# UNIPRO_REG register map
Vendor: Texas Instruments
Registers are 32-bit, access per field, reset 0x0 unless marked. A register's access mark holds for its fields unless they carry their own. Offsets are as the file gives them; [hi:lo] are bit positions; {n}, {i} and the like mark numbered series; 'fields as' and 'values as' point back to an identical list.

## UNIPRO_REG (part 2 of 2)
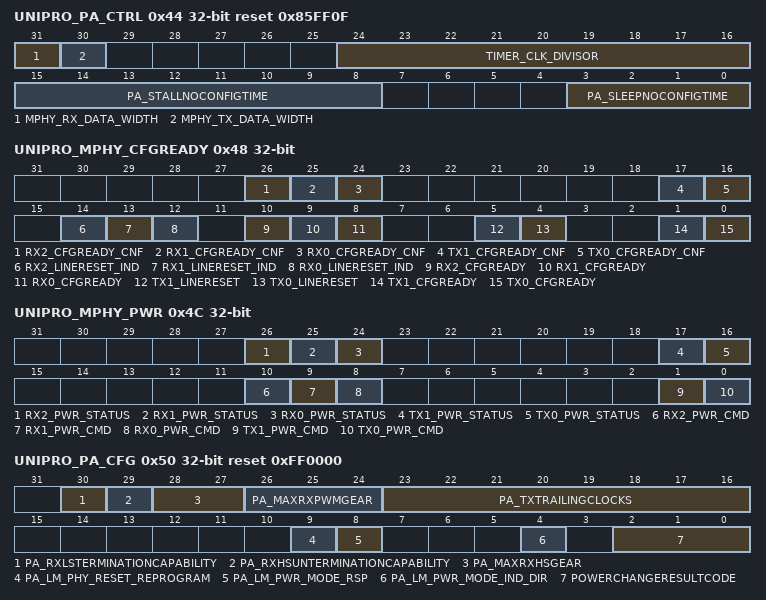
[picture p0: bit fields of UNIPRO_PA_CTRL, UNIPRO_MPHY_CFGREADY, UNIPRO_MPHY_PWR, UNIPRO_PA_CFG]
0x44 UNIPRO_PA_CTRL reset 0x85FF0F — This register programs UniPro PA general configuration and control.
  [31] MPHY_RX_DATA_WIDTH rw — Defines the width of the Data Bus on Rx. 0: 8 bits 1: 16 bits
  [30] MPHY_TX_DATA_WIDTH rw — Defines the width of the Data Bus on Tx. 0: 8 bits 1: 16 bits
  [24:16] TIMER_CLK_DIVISOR rw — Defines the ratio to be used for the generation of the timer clocks. Valid values 0x001-0x1FF. If CLKSEL_OPP = '0' the programmed value is used. If CLKSEL_OPP = '1' the value is multiplied by 2.
  [15:8] PA_STALLNOCONFIGTIME rw — Specifies the minimum time to wait between bursts in HS mode expressed in Symbol Intervals.
  [3:0] PA_SLEEPNOCONFIGTIME rw — Specifies the minimum time to wait between bursts in PWM mode expressed in Symbol Intervals.
0x48 UNIPRO_MPHY_CFGREADY — This register control MPHY_CFGREADY requests to M-TX/M-RX and monitors confirms.
  [26] RX2_CFGREADY_CNF ro — CFGREADY.cnf received for M-RX2. Cleared by HW when new command is issued.
  [25] RX1_CFGREADY_CNF ro — CFGREADY.cnf received for M-RX1. Cleared by HW when new command is issued.
  [24] RX0_CFGREADY_CNF ro — CFGREADY.cnf received for M-RX0. Cleared by HW when new command is issued.
  [17] TX1_CFGREADY_CNF ro — CFGREADY.cnf or LINERESET.cnf received for M-TX1. Cleared by HW when new command is issued.
  [16] TX0_CFGREADY_CNF ro — CFGREADY.cnf or LINERESET.cnf received for M-TX0. Cleared by HW when new command is issued.
  [14] RX2_LINERESET_IND rw — Indicate LINERESET occurred for M-RX2. Cleared by SW.
  [13] RX1_LINERESET_IND rw — Indicate LINERESET occurred for M-RX1. Cleared by SW.
  [12] RX0_LINERESET_IND rw — Indicate LINERESET occurred for M-RX0. Cleared by SW.
  [10] RX2_CFGREADY wo — Sets CFGREADY for M-RX2.
  [9] RX1_CFGREADY wo — Sets CFGREADY for M-RX1.
  [8] RX0_CFGREADY wo — Sets CFGREADY for M-RX0
  [5] TX1_LINERESET wo — Sets LINERESET for M-TX1.
  [4] TX0_LINERESET wo — Sets LINERESET for M-TX0
  [1] TX1_CFGREADY wo — Sets CFGREADY for M-TX1.
  [0] TX0_CFGREADY wo — Sets CFGREADY for M-TX0
0x4C UNIPRO_MPHY_PWR — Tx/Rx M-PHY power control
  [26] RX2_PWR_STATUS ro — Status of the M-RX2. Read 0x0: M-RX in OFF state Read 0x1: M-RX in ON state
  [25] RX1_PWR_STATUS ro — Status of the M-RX1. Read 0x0: M-RX in OFF state Read 0x1: M-RX in ON state
  [24] RX0_PWR_STATUS ro — Status of the M-RX0 Read 0x0: M-RX in OFF state Read 0x1: M-RX in ON state
  [17] TX1_PWR_STATUS ro — Status of the power control of M-TX1. Read 0x0: M-TX in OFF state Read 0x1: M-TX in ON state
  [16] TX0_PWR_STATUS ro — Status of the power control of M-TX0 Read 0x0: M-TX in OFF state Read 0x1: M-TX in ON state
  [10] RX2_PWR_CMD rw — Command for power control of M-RX2. 0x0: Command to change to OFF state 0x1: Command to change to ON state
  [9] RX1_PWR_CMD rw — Command for power control of M-RX1. 0x0: Command to change to OFF state 0x1: Command to change to ON state
  [8] RX0_PWR_CMD rw — Command for power control of M-RX0 0x0: Command to change to OFF state 0x1: Command to change to ON state
  [1] TX1_PWR_CMD rw — Command for power control of M-TX1. 0x0: Command to change to OFF state 0x1: Command to change to ON state
  [0] TX0_PWR_CMD rw — Command for power control of M-TX0 0x0: Command to change to OFF state 0x1: Command to change to ON state
0x50 UNIPRO_PA_CFG access not given reset 0xFF0000 — PHYSICAL ADAPTER CONFIGURATION REGISTER This register contains, amongst other, the PA_MIB.
  [30] PA_RXLSTERMINATIONCAPABILITY rw — Specifies whether or not the inbound link supports terminated line in LS mode.
  [29] PA_RXHSUNTERMINATIONCAPABILITY rw — Specifies whether or not the inbound link supports unterminated line in HS mode.
  [28:27] PA_MAXRXHSGEAR rw — Maximum RX High Speed Gears (HS), 0 means no HS available 0: NO_HS 1: HS_G1 2: HS_G2 3: HS_G3
  [26:24] PA_MAXRXPWMGEAR rw — Maximum RX Low Speed Gear (PWM) 0: Reserved 1: PWM_G1 2: PWM_G2 3: PWM_G3 4: PWM_G4 5: PWM_G5 6: PWM_G6 7: PWM_G7
  [23:16] PA_TXTRAILINGCLOCKS rw — Number of PHY byte clock cycles forced without data before a mode change from FAST_STATE or SLOW_STATE to SLEEP_STATE, or before data transmission pause while in FAST_STATE or SLOW_STATE.
  [9] PA_LM_PHY_RESET_REPROGRAM wo — Indicates SW has reprogrammed PHY attributes after a PHY_RESET. 0:SW has not reprogrammed PHY attributes. 1:SW has reprogrammed PHY attributes.
  [8] PA_LM_PWR_MODE_RSP wo — Response to PA_LM_PWR_MODE.ind Writing a 1 to this field confirms that PA_LM_PWR_MODE.ind is accepted and PA_PWRModeUserData fields are updated.
  [4] PA_LM_PWR_MODE_IND_DIR — Indicates whether PA_LM_PWR_MODE.ind was from local or remote request. 0: remote request 1: local request (access RW WtoClr)
  [2:0] POWERCHANGERESULTCODE — The code of the accepted Power Change requets 0: PWR_OK - The request was accepted. 1: PWR_LOCAL - The local request was successfully applied 2: PWR_REMOTE - The remote request was successfully applied 3: PWR_BUSY - The request was aborted due to concurrent requests 4: PWR_ERROR_CAP - The request was rejected due to an impossible configuration. 5: PWR_FATAL_ERROR - The request was aborted due to a communication problem. The link may be inoperable. 6-7: reserved Write to clear. (access RW WtoClr)
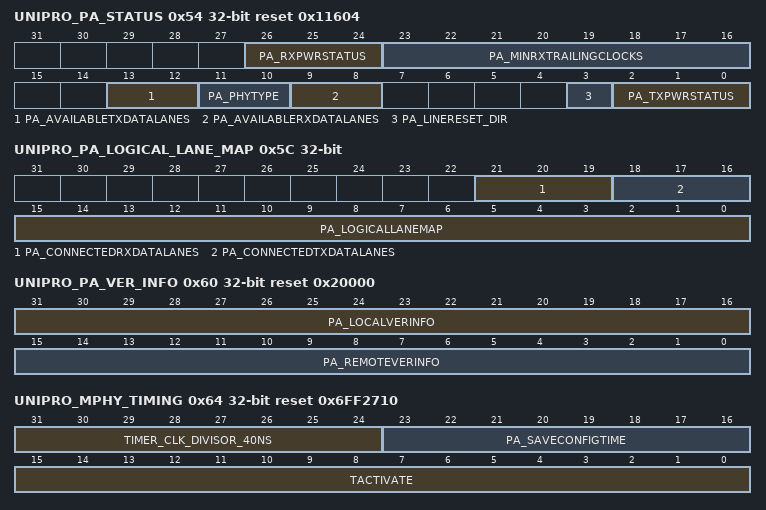
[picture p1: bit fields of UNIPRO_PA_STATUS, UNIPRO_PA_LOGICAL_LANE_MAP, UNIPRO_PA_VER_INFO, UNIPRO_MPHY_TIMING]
0x54 UNIPRO_PA_STATUS ro reset 0x11604 — PHYSICAL ADAPTER STATUS REGISTER This register contains, amongst other, the PA_MIB.
  [26:24] PA_RXPWRSTATUS — Power status for Rx 0x0 Off_state 0x1 Fast_state 0x2 Slow_state 0x3 Hibernate_state (ULPS State) 0x4 Sleep_state (STOP state) Reading this field actually triggers an M-CTRL-CFGGET request to the M-RX. The RX_FSM attribute is read for logical lane 0 and this is the value returned.
  [23:16] PA_MINRXTRAILINGCLOCKS — Minimum number of PHY byte clock without data to receive before a mode change from FAST_STATE or SLOW_STATE to SLEEP_STATE, or before a pause in data transmission when in FAST_STATE or SLOW_STATE
  [13:12] PA_AVAILABLETXDATALANES — 0x0 1 lane 0x1 2 lanes 0x2 3 lanes 0x3 4 lanes (Programmed_Value = MIPI_Specified_Value - 1)
  [11:10] PA_PHYTYPE — 0x0: encode D PHY 0x1: M PHY 0x2: reserved 0x3: reserved
  [9:8] PA_AVAILABLERXDATALANES — 0x0 1 lane 0x1 2 lanes 0x2 3 lanes 0x3 4 lanes (Programmed_Value = MIPI_Specified_Value - 1)
  [3] PA_LINERESET_DIR — Indicates whether LINERESET was for M-RX or M-TX 0x0 M-RX 0x1 M-TX
  [2:0] PA_TXPWRSTATUS — Power status for Tx 0x0 Off_state 0x1 Fast_state 0x2 Slow_state 0x3 Hibernate_state (ULPS State) 0x4 Sleep_state (STOP state) Reading this field actually triggers an M-CTRL-CFGGET request to the M-TX. The TX_FSM attribute is read for logical lane 0 and this is the value returned.
0x5C UNIPRO_PA_LOGICAL_LANE_MAP — PHYSICAL ADAPTER STATUS REGISTER This register contains, amongst other, the PA_MIB. Note: this register is only writable in PHY Test mode
  [21:19] PA_CONNECTEDRXDATALANES rw — Number of Rx Data Lanes Connected 0x0 0 lanes 0x1 1 lane 0x2 2 lanes 0x3 3 lanes 0x4 4 lanes
  [18:16] PA_CONNECTEDTXDATALANES rw — Number of Tx Data Lanes Connected 0x0 0 lanes 0x1 1 lane 0x2 2 lanes 0x3 3 lanes 0x4 4 lanes
  [15:0] PA_LOGICALLANEMAP rw — Logical to Physical Lane mapping. Fields contain a valid value after succesfull Linkstartup sequence. Tx Lanes: Bits 1..0: Physical lane of logical lane 0 Bits 3..2: Physical lane of logical lane 1 Bits 5..4: Physical lane of logical lane 2 Bits 7..6: Physical lane of logical lane 3 Rx Lanes: Bits 9..8: Physical lane of logical lane 0 Bits 11..10: Physical lane of logical lane 1 Bits 13..12: Physical lane of logical lane 2 Bits 15..14: Physical lane of logical lane 3
0x60 UNIPRO_PA_VER_INFO reset 0x20000 — This register contains version information.
  [31:16] PA_LOCALVERINFO rw — Local Version Info. Delivered during the Link Startup Sequence to the peer and stored to there.
  [15:0] PA_REMOTEVERINFO ro — Remote Peer's version information. Available after Link Startup Sequence.
0x64 UNIPRO_MPHY_TIMING rw reset 0x6FF2710 — This register defines the timing parameters that need to be respected on the M-PHY Control Interface..
  [31:24] TIMER_CLK_DIVISOR_40NS — Defines the ratio to be used for the generation of a 40ns clock from UniPro OCP functional clock. Legal values 0x01 - 0xFF. If CLKSEL_OPP = '0' the programmed value is used. If CLKSEL_OPP = '1' the value is multiplied by 2.
  [23:16] PA_SAVECONFIGTIME — Minimum reconfiguration time (expressed in 40 ns intervals). Downgraded value updated after Linkstartup completes.
  [15:0] TACTIVATE — The period of time that M-TX shall drive DIF-N on the lines. The time is expressed in us. This field should be programmed to satisfy MPHY’s requirements for TACTIVATE and T_LINE_RESET. The time should be greater than MAX(TACTIVATE, T_LINE_RESET).
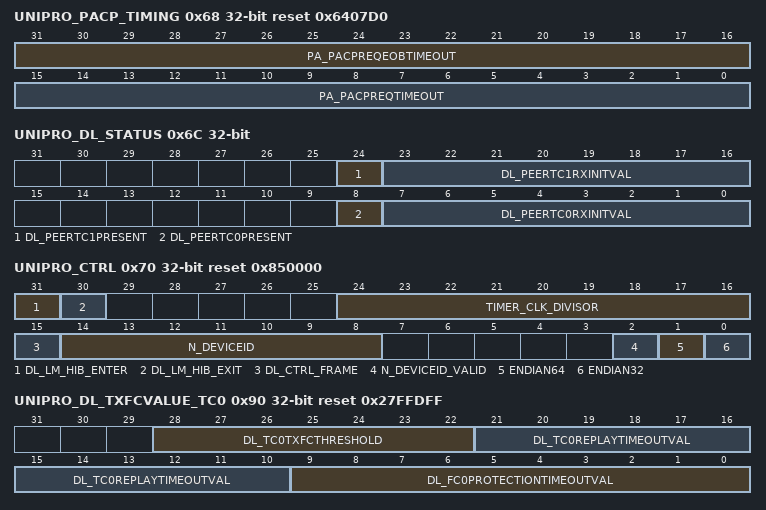
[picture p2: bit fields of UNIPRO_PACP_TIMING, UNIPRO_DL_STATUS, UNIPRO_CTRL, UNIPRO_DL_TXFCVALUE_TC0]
0x68 UNIPRO_PACP_TIMING rw reset 0x6407D0 — This register contains the timeout values for .
  [31:16] PA_PACPREQEOBTIMEOUT — Expiration value of the PACP_REQUEST_EoB_TIMER. The value is expressed in us.
  [15:0] PA_PACPREQTIMEOUT — Expiration value of the PACP_REQUEST_TIMER. The value is expressed in us.
0x6C UNIPRO_DL_STATUS ro — DATA LINK STATUS REGISTER This register contains DL status information.
  [24] DL_PEERTC1PRESENT — This status bit is updated during the initilization phase following the DL_ENABLE_LAYER.req() command. It is set to zero by default. 0: indicates that the Peer Device does not support TC0 1: indicates that the Peer Device does support TC0
  [23:16] DL_PEERTC1RXINITVAL — This register get set after DL initilization. It is loaded with the credit value sent by the remote device on the first AFC exchange during the boot sequence.
  [8] DL_PEERTC0PRESENT — This status bit is updated during the initilization phase following the DL_ENABLE_LAYER.req() command. It is set to zero by default. 0: indicates that the Peer Device does not support TC0 1: indicates that the Peer Device does support TC0
  [7:0] DL_PEERTC0RXINITVAL — This register get set after DL initilization. It is loaded with the credit value sent by the remote device on the first AFC exchange during the boot sequence.
0x70 UNIPRO_CTRL reset 0x850000 — This register regroups UniPro interface general control and configuration parameters
  [31] DL_LM_HIB_ENTER wo — Write 1 to this field to trigger DL_LM_HIBERNATE_ENTER.req
  [30] DL_LM_HIB_EXIT wo — Write 1 to this field to trigger DL_LM_HIBERNATE_EXIT.req
  [24:16] TIMER_CLK_DIVISOR rw — Defines the ratio to be used for the generation of the Timer clock from UniPro OCP functional clock. Legal values 0x001 - 0x1FF. If CLKSEL_OPP = '0' the programmed value is used. If CLKSEL_OPP = '1' the value is multiplied by 2.
  [15] DL_CTRL_FRAME ro — When 1, Indicates that Data Link engine has scheduled control frames whose transmission is not completed. When 0, all scheduled control frames in Data Link have been transmitted.
  [14:8] N_DEVICEID rw — local DeviceID value
  [2] N_DEVICEID_VALID rw — N_DeviceID attribute is valid. 0: N_DeviceID attribute is not valid. DeviceIDOffset = 0. 1: N_DeviceID attribute is valid. DeviceIDOffset = DestDeviceID_Enc - N_DeviceID
  [1] ENDIAN64 rw — 64b word Data Receive endianness conversion control 0 : no endianness adaptation 1 : the two 32b halves constituting the 64b are swizzled
  [0] ENDIAN32 rw — 32b word Data Receive endianness conversion control 0 : no endianness adaptation 1 : bytes in a 32b word are swizzled
0x74 UNIPRO_MPHY_TIMING2 reset 0x2710 — This register defines timing parameters on the M-PHY Control Interface.
  [15:0] PA_HIBERN8TIME rw — The period of time in which M-TX must remain in Hibern8 once entered. Time is expressed in usec.
0x7C UNIPRO_PA_LM_ENABLE_LAYER wo — PHYSICAL ADAPTER Command writing to the register initiates a link start up. The DME command has been renamedas PA_LM_ENABLE.req
  [31:0] VALUE
0x80 UNIPRO_DL_LM_ENABLE_LAYER wo — Data Link Layer Command writing to the register initializes the data link layer. This corresponds to the DME command DL_LM_ENABLE_LAYER.req
  [31:0] VALUE
0x84 UNIPRO_N_LM_ENABLE_LAYER wo — Network Layer Command writing to the memory mapped address initiates a N_LM_ENABLE.req
  [31:0] VALUE
0x88 UNIPRO_T_LM_ENABLE_LAYER wo — Transport Layer Command writing to the memory mapped address initiates a T_LM_ENABLE.req ref. to UniPro 1.1 release [3].
  [31:0] VALUE
0x8C UNIPRO_ENDPOINTRESET wo — PHYSICAL ADAPTER Command writing to the register initiates transmission of an EndPointReset trgigger over the link to the peer device.
  [31:0] VALUE
0x90 UNIPRO_DL_TXFCVALUE_TC0 reset 0x27FFDFF — DATA LINK TX flow control value This register contains the timeout and threshold values for DL MIB for transmitter side
  [28:22] DL_TC0TXFCTHRESHOLD rw — Threshold for triggering an AFC0 frame with REQ bit set to request flow control update from the remote end
  [21:10] DL_TC0REPLAYTIMEOUTVAL rw — 1 to 4095 us. (1 MHz clock derived from 1.6GHz) Timeout value for triggering retransmission of TC0 frame. Zero indicates timer is OFF
  [9:0] DL_FC0PROTECTIONTIMEOUTVAL rw — 1 to 1023 us. (1 MHz clock derived from 1.6GHz) Timeout value for triggering a request to remote end for flow control update. Zero indicates timer is OFF
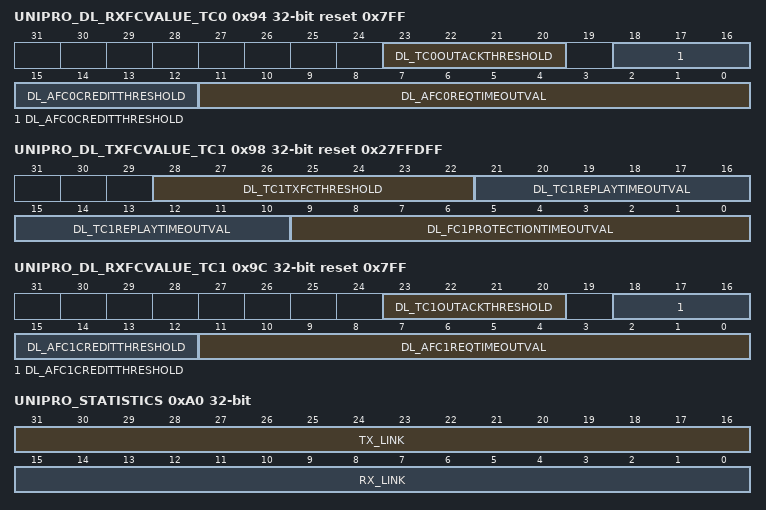
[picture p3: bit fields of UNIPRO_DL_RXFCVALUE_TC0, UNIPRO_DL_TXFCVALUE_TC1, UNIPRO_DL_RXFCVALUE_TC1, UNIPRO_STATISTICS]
0x94 UNIPRO_DL_RXFCVALUE_TC0 reset 0x7FF — DATA LINK RX flow control values This register contains the timeout and threshold values for DL MIB for receiver side
  [23:20] DL_TC0OUTACKTHRESHOLD rw — 0 to 15. Number of outstanding Acknowledgements for TC0
  [18:12] DL_AFC0CREDITTHRESHOLD rw — 0 to 127 Threshold for AFC triggering based on available credits
  [11:0] DL_AFC0REQTIMEOUTVAL rw — 1 to 4095 us. (1 MHz clock derived from 1.6GHz) TimeOut value for AFC triggering on receiver side. Zero indicates that the timer is OFF
0x98 UNIPRO_DL_TXFCVALUE_TC1 reset 0x27FFDFF — DATA LINK TX flow control value This register contains the timeout and threshold values for DL MIB for transmitter side
  [28:22] DL_TC1TXFCTHRESHOLD rw — Threshold for triggering an AFC1 frame with REQ bit set to request flow control update from the remote end
  [21:10] DL_TC1REPLAYTIMEOUTVAL rw — 1 to 4095 us. (1 MHz clock derived from 1.6GHz) Timeout value for triggering retransmission of TC1 frame. Zero indicates timer is OFF
  [9:0] DL_FC1PROTECTIONTIMEOUTVAL rw — 1 to 1023 us. (1 MHz clock derived from 1.6GHz) Timeout value for triggering a request to remote end for flow control update. Zero indicates timer is OFF
0x9C UNIPRO_DL_RXFCVALUE_TC1 reset 0x7FF — DATA LINK RX flow control values This register contains the timeout and threshold values for DL MIB for receiver side
  [23:20] DL_TC1OUTACKTHRESHOLD rw — 0 to 15. Number of outstanding Acknowledgements for TC1
  [18:12] DL_AFC1CREDITTHRESHOLD rw — 0 to 127 Threshold for AFC triggering based on available credits
  [11:0] DL_AFC1REQTIMEOUTVAL rw — 1 to 4095 us. (1 MHz clock derived from 1.6GHz) TimeOut value for AFC triggering on receiver side. Zero indicates that the timer is OFF
0xA0 UNIPRO_STATISTICS ro — Status register containing Link Quality Statistics information.
  [31:16] TX_LINK — This field indicates the number of errors detected on Tx link. It is incremented every time an NAC is received indicating a Tx link error.
  [15:0] RX_LINK — This field indicates the number of CRC errors detected on Rx link. It is incremented by one every time a CRC error on Rx link causes NAC transmission.
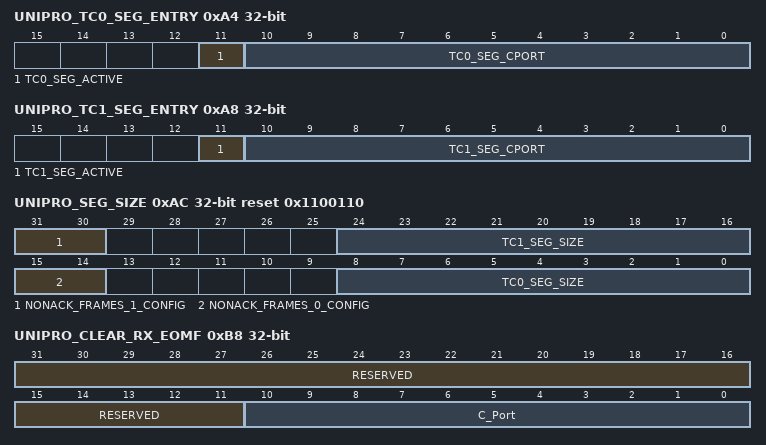
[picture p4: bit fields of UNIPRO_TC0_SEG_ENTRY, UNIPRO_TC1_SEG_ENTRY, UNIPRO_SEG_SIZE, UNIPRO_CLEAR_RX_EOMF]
0xA4 UNIPRO_TC0_SEG_ENTRY — Holds current C-Port entry under TN_ACC segmentation process on traffic class 0, and flag indicating non-empty segmentation list
  [11] TC0_SEG_ACTIVE rw — active list submitted to segmentation list exist for TC0
  [10:0] TC0_SEG_CPORT rw — current C-Port under TN_ACC seg process for TC0
0xA8 UNIPRO_TC1_SEG_ENTRY — Holds current C-Port entry under TN_ACC segmentation process on traffic class 1, and flag indicating non-empty segmentation list
  [11] TC1_SEG_ACTIVE rw — active list submitted to segmentation list exist for TC1
  [10:0] TC1_SEG_CPORT rw — current C-Port under TN_ACC seg process for TC1
0xAC UNIPRO_SEG_SIZE reset 0x1100110 — Maximum segmentation packet size for traffic classes 0 and 1
  [31:30] NONACK_FRAMES_1_CONFIG rw — Defines the Non acknowledged frames windows size in the transmit data link layer path for traffic class 1. The real number of non acknowledged frames is defined as : NWS(TC1) = pow (2, NonAck_Frames_1_Config + 1)
  [24:16] TC1_SEG_SIZE rw — Traffic class 1 Transport segment payload size
  [15:14] NONACK_FRAMES_0_CONFIG rw — Defines the Non acknowledged frames windows size in the transmit data link layer path for traffic class 0. The real number of non acknowledged frames is defined as : NWS(TC0) = pow (2, NonAck_Frames_0_Config + 1)
  [8:0] TC0_SEG_SIZE rw — Traffic class 0 Transport segment payload size
0xB0 UNIPRO_CPORT_BASE — C-Port structures array base address
  [31:7] CPORT_BASE rw — 128 bytes boundary aligned address
0xB4 UNIPRO_NUM_CPORTS reset 0x1 — Defines the number of available CPORTS.
  [11:0] T_NUM_CPORTS rw — Defines the number of available C-Ports. Used to calculate valid C-Port range. Allowed values 1 to 2048.
0xB8 UNIPRO_CLEAR_RX_EOMF access not given — coherent access command to clear the EoMF/EoM flag in C-Port structure
  [31:11] RESERVED — (access NA)
  [10:0] C_Port wo — command parameter : C-Port entry in CPORT structures array
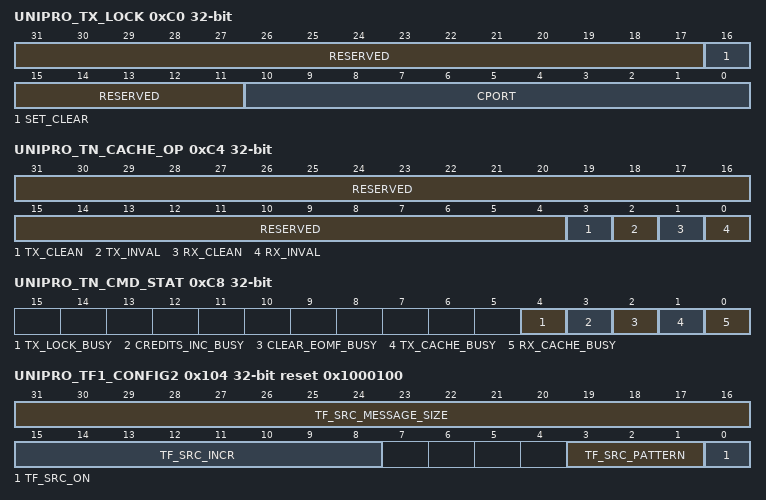
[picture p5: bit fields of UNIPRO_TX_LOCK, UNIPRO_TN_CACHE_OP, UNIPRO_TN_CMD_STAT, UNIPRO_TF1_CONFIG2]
0xC0 UNIPRO_TX_LOCK access not given — Memory mapped command used for coherent set/clear of the TX_LOCK bit in the C-Port descriptor.
  [31:17] RESERVED — (access NA)
  [16] SET_CLEAR rw — command parameter : specifies operation type 0 : TX_LOCK should be cleared 1 : TX_LOCK should be set
  [15:11] RESERVED — (access NA)
  [10:0] CPORT rw — command parameter : cport entry in CPORT structures array
0xC4 UNIPRO_TN_CACHE_OP access not given — clean /or invalidate commands to TN_ACC caches structures
  [31:4] RESERVED — (access NA)
  [3] TX_CLEAN wo — clean all dirty Tx cache entries
  [2] TX_INVAL wo — invalidate all Tx cache entries
  [1] RX_CLEAN wo — clean all dirty Rx cache entries
  [0] RX_INVAL wo — invalidate all Rx cache entries
0xC8 UNIPRO_TN_CMD_STAT ro — status of pending register-mapped commands
  [4] TX_LOCK_BUSY — Tx lock command is ongoing
  [3] CREDITS_INC_BUSY — credits increment command ongoing
  [2] CLEAR_EOMF_BUSY — EoMF clear ongoing
  [1] TX_CACHE_BUSY — operation on Tx cache ongoing
  [0] RX_CACHE_BUSY — operation on Rx cache ongoing
0xE0 UNIPRO_PA_PWRMODEUSERDATA0 rw — PA_PWRModeUserData received with the PA_LM_PWR_MODE indication and sent with PA_LM_PWR_MODE confirm.
  [31:0] PWRMODEUSERDATA — PA_PWRModeUserData bytes 3..0
0xE4 UNIPRO_PA_PWRMODEUSERDATA1 rw — PA_PWRModeUserData received with the PA_LM_PWR_MODE indication and sent with PA_LM_PWR_MODE confirm.
  [31:0] PWRMODEUSERDATA — PA_PWRModeUserData bytes 7..4
0xE8 UNIPRO_PA_PWRMODEUSERDATA2 rw — PA_PWRModeUserData received with the PA_LM_PWR_MODE indication and sent with PA_LM_PWR_MODE confirm.
  [31:0] PWRMODEUSERDATA — PA_PWRModeUserData bytes 11..8
0xEC UNIPRO_PA_PWRMODEUSERDATA3 rw — PA_PWRModeUserData received with the PA_LM_PWR_MODE indication and sent with PA_LM_PWR_MODE confirm.
  [31:0] PWRMODEUSERDATA — PA_PWRModeUserData bytes 15..11
0xF0 UNIPRO_PA_PWRMODEUSERDATA4 rw — PA_PWRModeUserData received with the PA_LM_PWR_MODE indication and sent with PA_LM_PWR_MODE confirm.
  [31:0] PWRMODEUSERDATA — PA_PWRModeUserData bytes 19..16
0xF4 UNIPRO_PA_PWRMODEUSERDATA5 rw — PA_PWRModeUserData received with the PA_LM_PWR_MODE indication and sent with PA_LM_PWR_MODE confirm.
  [31:0] PWRMODEUSERDATA — PA_PWRModeUserData bytes 23..20
0x100 UNIPRO_TF1_CONFIG1 reset 0x7FF — Test Feature
  [10:0] TF_TST_CPORTID rw — Select which CPORT the TestFeature 1 is connected to.
0x104 UNIPRO_TF1_CONFIG2 reset 0x1000100 — Test Feature
  [31:16] TF_SRC_MESSAGE_SIZE rw — Size of each generated message.
  [15:8] TF_SRC_INCR rw — Increment value between two consecutive byte
  [3:1] TF_SRC_PATTERN ro — 0: Sawtooth Others: reserved
  [0] TF_SRC_ON rw — 0: test feature is not active 1: test feature is active SW programs this field to enable/disable the test feature instance. HW resets the field to 0 when all messages have been transferred (as defined in TF_SRC_MESSAGE_COUNT).
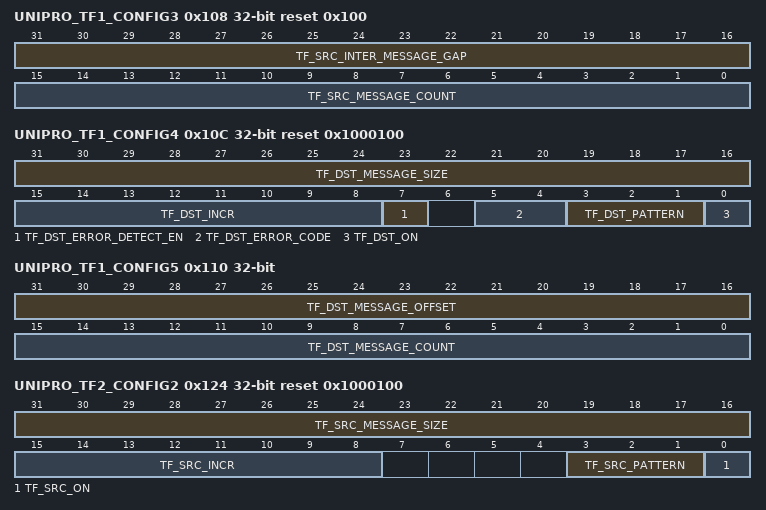
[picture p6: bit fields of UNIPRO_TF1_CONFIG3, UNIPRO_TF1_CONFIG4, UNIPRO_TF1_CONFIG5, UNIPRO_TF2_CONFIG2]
0x108 UNIPRO_TF1_CONFIG3 rw reset 0x100 — Test Feature
  [31:16] TF_SRC_INTER_MESSAGE_GAP — The time between 2 messages (timeout period). 0 to 65535 us (works with a 1MHz clock derived from the functional clock).
  [15:0] TF_SRC_MESSAGE_COUNT — The number of messages generated. Zero indicates infinite number. HW shall decrement this field when a message is sent.
0x10C UNIPRO_TF1_CONFIG4 reset 0x1000100 — Test Feature
  [31:16] TF_DST_MESSAGE_SIZE rw — Size of received test message.
  [15:8] TF_DST_INCR rw — The expected increment between two received bytes. In case of an unexpected byte value HW overwrites this field with the actual wrong increment.
  [7] TF_DST_ERROR_DETECT_EN rw — Error detection enable
  [5:4] TF_DST_ERROR_CODE rw — Error Code that generated the TstDst. This field is updated by HW when TstDst detects an error: 0 : NO ERROR 1 : MSG_CORRUPT - segments of the incoming message have been dropped due to an L4 error (CSV or CSD) 2 : INVALID_MSG_SIZE - Mismatch between incoming Message lenght and TF_DST_MESSAGE_SIZE 3 : UNEXPECTED_BYTE_VALUE - Mismatch in the increment between the consecutive bytes in the incoming Message an TF_DST_INCR
  [3:1] TF_DST_PATTERN ro — Expected received Pattern
  [0] TF_DST_ON rw — 0: analyzer is inactive 1: analyzer is active SW programs this field to enable/disable the test feature instance. HW resets the field to 0 when the first error is discovered in the incoming message stream.
0x110 UNIPRO_TF1_CONFIG5 rw — Test Feature
  [31:16] TF_DST_MESSAGE_OFFSET — Offset of the error from start of message. This value is represents the index, starting from 1, of the byte with an incorrect increment. It's reset to zero after analyzing every incoming Message and finding no errors within it.
  [15:0] TF_DST_MESSAGE_COUNT — Number of received messages. Incremented by HW on each EoM received for the CPORT_UNDER_TEST regardless of the correctness of the message.
0x114 UNIPRO_TF1_CONFIG6 rw reset 0x100 — Test Feature
  [31:0] TF_DST_FC_CREDIT — Number of credits passed to creditflow. This number can not exceed the MAXE2EFCcredit set for localbuffer size.
0x118 UNIPRO_TF1_CONFIG7 rw reset 0x100 — Test Feature
  [31:0] TF_DST_INITIAL_FC_CREDITS — The initial number of credits passed by the TstDst after enabling TstDst. This number can not exceed the MAXE2EFCcredit set for localbuffer size.
0x11C UNIPRO_TF1_CONFIG8 — Test Feature
  [15:0] TF_DST_INTER_FC_TOKEN_GAP rw — Gap between 2 tokens. 0 to 65535 us (works with a 1MHz clock derived from the functional clock).
0x120 UNIPRO_TF2_CONFIG1 reset 0x7FF — Test Feature
  fields as UNIPRO_TF1_CONFIG1
0x124 UNIPRO_TF2_CONFIG2 reset 0x1000100 — Test Feature
  [31:16] TF_SRC_MESSAGE_SIZE rw — Size of each generated message
  [15:8] TF_SRC_INCR rw — Increment value between two consecutive byte
  [3:1] TF_SRC_PATTERN ro — 0: Sawtooth Others: reserved
  [0] TF_SRC_ON rw — 0: test feature is not active 1: test feature is active SW programs this field to enable/disable the test feature instance. HW resets the field to 0 when all messages have been transferred (as defined in TF_SRC_MESSAGE_COUNT).
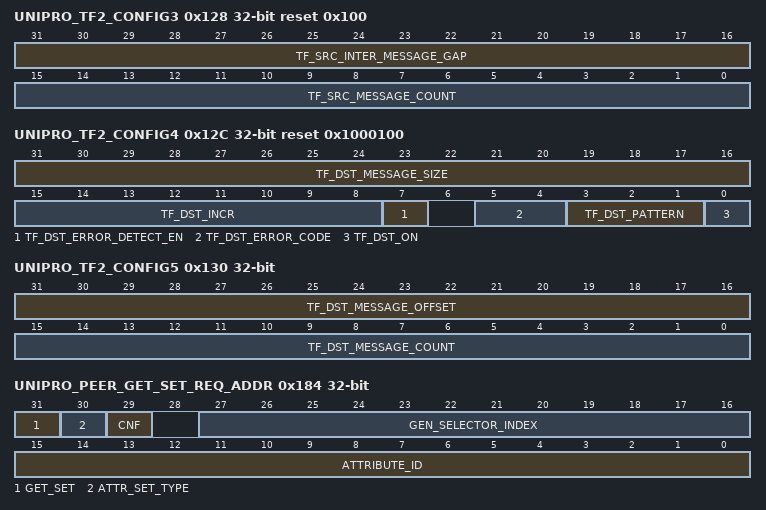
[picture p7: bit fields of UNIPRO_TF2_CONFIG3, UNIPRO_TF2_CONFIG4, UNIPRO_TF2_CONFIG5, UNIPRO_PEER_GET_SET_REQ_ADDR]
0x128 UNIPRO_TF2_CONFIG3 rw reset 0x100 — Test Feature
  [31:16] TF_SRC_INTER_MESSAGE_GAP — The time between 2 messages (timeout period) 0 to 65535 us (works with a 1MHz clock derived from the functional clock).
  [15:0] TF_SRC_MESSAGE_COUNT — The number of messages generated. Zero indicates infinite number. HW shall decrement this field when a message is sent.
0x12C UNIPRO_TF2_CONFIG4 reset 0x1000100 — Test Feature
  fields as UNIPRO_TF1_CONFIG4
0x130 UNIPRO_TF2_CONFIG5 rw — Test Feature
  fields as UNIPRO_TF1_CONFIG5
0x134 UNIPRO_TF2_CONFIG6 rw reset 0x100 — Test Feature
  fields as UNIPRO_TF1_CONFIG6
0x138 UNIPRO_TF2_CONFIG7 rw reset 0x100 — Test Feature
  fields as UNIPRO_TF1_CONFIG7
0x13C UNIPRO_TF2_CONFIG8 — Test Feature
  fields as UNIPRO_TF1_CONFIG8
0x180 UNIPRO_PEER_SET_REQ_DATA rw — Contains value to be written to remote attribute by DME_PEER_SET.req .
  [31:0] VALUE — Attribute value
0x184 UNIPRO_PEER_GET_SET_REQ_ADDR — Parameters for DME_PEER_GET.req and DME_PEER_SET.req
  [31] GET_SET rw — Command direction: 0 : Read (Get) 1 : Write (Set)
  [30] ATTR_SET_TYPE rw — For SET command: How Attribute is set: 0 : Normal 1 : Static For GET command: Reserved
  [29] CNF rw — Indicates PEER_GET/SET request has completed
  [27:16] GEN_SELECTOR_INDEX rw — Targeted M-PHY data lane, CPort, or test feature.
  [15:0] ATTRIBUTE_ID rw — Targeted Attribute ID. Range: 0x0000 to 0x7FFF
0x188 UNIPRO_PEER_GET_CNF_DATA rw — Attribute value for DME_PEER_SET.cnf or DME_PEER_GET.cnf to be sent from local device to remote device.
  [31:0] VALUE — Attribute value
    0=newEnum1
0x18C UNIPRO_PEER_GET_SET_CNF_RESULT — Result code for DME_PEER_GET.cnf or DME_PEER_SET.cnf that will be sent from local device to remote device.
  [3:0] CONFIG_RESULT_CODE rw — Indicates the result of the PEER_GET or PEER_SET request. SUCCESS = 0 INVALID_MIB_ATTRIBUTE = 1 INVALID_MIB_ATTRIBUTE_VALUE = 2 READ_ONLY_MIB_ATTRIBUTE = 3 WRITE_ONLY_MIB_ATTRIBUTE = 4 BAD_INDEX = 5 LOCKED_MIB_ATTRIBUTE = 6 BAD_TEST_FEATURE_INDEX = 7 PEER_COMMUNICATION_FAILURE = 8 BUSY = 9 DME_FAILURE = 10
0x190 UNIPRO_REMOTE_SET_REQ_DATA ro — Attribute value received from remote device's DME_PEER_SET.req, to be written locally
  [31:0] VALUE — Attribute value
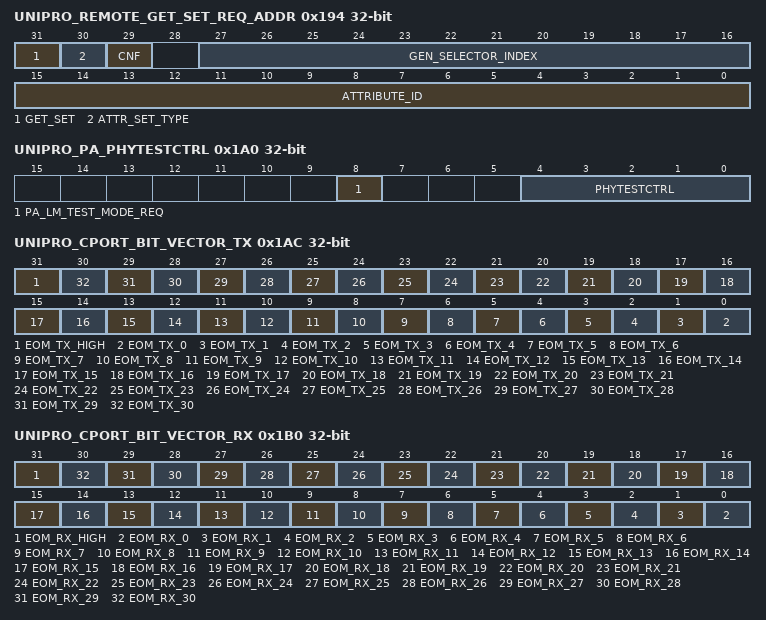
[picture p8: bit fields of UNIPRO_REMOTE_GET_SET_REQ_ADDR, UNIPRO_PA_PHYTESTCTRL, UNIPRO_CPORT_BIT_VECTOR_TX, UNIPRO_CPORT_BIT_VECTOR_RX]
0x194 UNIPRO_REMOTE_GET_SET_REQ_ADDR ro — Parameters for DME_PEER_GET.req and DME_PEER_SET.req coming from remote device.
  [31] GET_SET — Command direction: 0 : Read (Get) 1 : Write (Set)
  [30] ATTR_SET_TYPE — For SET command: How Attribute is set: 0 : Normal 1 : Static For GET command: Reserved
  [29] CNF — Cnf: defines the behavior of the receiving PA Layer 0: no PACP_SET_cnf frame shall be sent 1: a PACP_SET_cnf frame shall be sent to acknowledge the reception of the PACP_SET_req frame and to return the result of the operation
  [27:16] GEN_SELECTOR_INDEX — Targeted M-PHY data lane, CPort, or test feature.
  [15:0] ATTRIBUTE_ID — Targeted Attribute ID. Range: 0x0000 to 0x7FFF
0x198 UNIPRO_LOCAL_GET_CNF_DATA ro — Attribute value sent back from the remote device following a DME_PEER_GET.req issued from local device.
  [31:0] VALUE — Attribute value
0x19C UNIPRO_LOCAL_GET_SET_CNF_RESULT ro — Result code sent back from the remote device following a DME_PEER_GET.req or DME_PEER_SET.req issued from local device.
  [3:0] CONFIG_RESULT_CODE — Indicates the result of the PEER_GET or PEER_SET request. SUCCESS = 0 INVALID_MIB_ATTRIBUTE = 1 INVALID_MIB_ATTRIBUTE_VALUE = 2 READ_ONLY_MIB_ATTRIBUTE = 3 WRITE_ONLY_MIB_ATTRIBUTE = 4 BAD_INDEX = 5 LOCKED_MIB_ATTRIBUTE = 6 BAD_TEST_FEATURE_INDEX = 7 PEER_COMMUNICATION_FAILURE = 8 BUSY = 9 DME_FAILURE = 10
0x1A0 UNIPRO_PA_PHYTESTCTRL — PHY test control register
  [8] PA_LM_TEST_MODE_REQ rw — Generated by the DME to request the local PA Layer to set the PA Layer of the peer Device to a specified test mode.
  [4:0] PHYTESTCTRL rw — PHY Test Feature control register b0 : ContBurst b1 : CfgReady b2 : LineReset b3 : TestPatternTransmit b4 : TestPatternSelect
0x1A4 UNIPRO_PA_PACPFRAMECOUNT access not given — PACP frame counter
  [31:0] PACPFRAMECOUNT — Incremented by one if the received PACP frame has a validFunctionID and passes the checksum verification. Automatically rolls over to zero on an overflow. A PA_LM_SET request to PA_PACPFrameCount shall set the counter to zero. (access RW WtoClr)
0x1A8 UNIPRO_PA_PACPERRORCOUNT access not given — PACP error counter
  [31:0] PACPERRORCOUNT — Incremented by one for each PACP start symbol that is not part of a PACP frame that incremented PA_PACPFrameCount. Automatically rolls over to zero on an overflow. A PA_LM_SET request to PA_PACPFrameCount shall set the counter to zero. (access RW WtoClr)
0x1AC UNIPRO_CPORT_BIT_VECTOR_TX access not given — Bit vector of TX EoMs
  [31] EOM_TX_HIGH — (access RW W1toClr)
  [n] EOM_TX_{n} (n=0..30) — (access RW W1toClr)
0x1B0 UNIPRO_CPORT_BIT_VECTOR_RX access not given — Bit vector of RX EoMs
  [31] EOM_RX_HIGH — (access RW W1toClr)
  [n] EOM_RX_{n} (n=0..30) — (access RW W1toClr)
0x800 UNIPRO_TMPI_MTX0_ATTRIBUTE_0_3 rw — Register mapped access to T-MPI attributes
  [31:0] VALUE — Note: these are not physical registers within Unipro, but are address ranges to be used for accessing T-MPI attributes.
0x8FC UNIPRO_TMPI_MTX0_ATTRIBUTE_252_255 rw — Register mapped access to T-MPI attributes
  fields as UNIPRO_TMPI_MTX0_ATTRIBUTE_0_3
